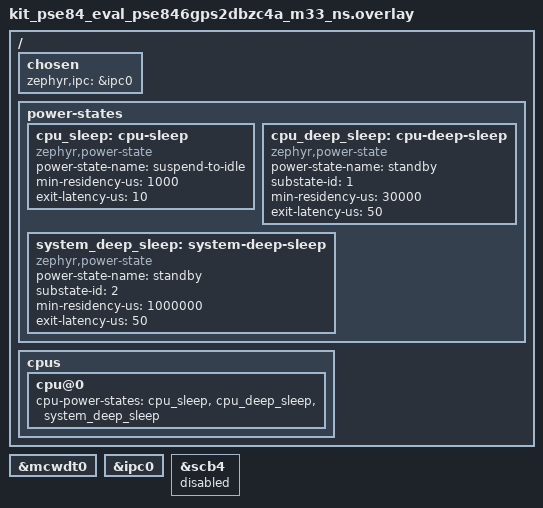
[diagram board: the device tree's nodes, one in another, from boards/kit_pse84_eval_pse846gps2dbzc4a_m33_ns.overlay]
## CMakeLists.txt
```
cmake_minimum_required(VERSION 3.20.0)

find_package(Zephyr REQUIRED HINTS $ENV{ZEPHYR_BASE})

# Inject the z_pm out-of-tree TF-M secure partition into the TF-M build.
# Set after find_package(Zephyr) so zephyr_property_target exists, but
# before project() so the TF-M ExternalProject CMake picks it up.
set(Z_PM_PARTITION_DIR ${CMAKE_CURRENT_LIST_DIR}/../tfm_partitions/z_pm)
set_property(TARGET zephyr_property_target
    APPEND PROPERTY TFM_CMAKE_OPTIONS
    -DTFM_EXTRA_MANIFEST_LIST_FILES=${Z_PM_PARTITION_DIR}/manifest_list.yaml
    -DTFM_EXTRA_PARTITION_PATHS=${Z_PM_PARTITION_DIR}
    # Round-7 debug: halt (spin) in tfm_core_panic instead of doing
    # NVIC_SystemReset. Lets a debugger read the exception frame that
    # BusFault_Handler / SecureFault_Handler stashed via EXCEPTION_INFO().
    # Remove for production builds.
    -DCONFIG_TFM_HALT_ON_CORE_PANIC=ON
)

project(cm33_ns_blinki)

# Drop the SoC's default pm_state_set + its PRE_KERNEL_1 SYS_INIT
# (which bus-faults from NS under TF-M when CONFIG_PM=y). We provide
# our own pm_state_set in src/power.c.
get_target_property(zephyr_sources zephyr SOURCES)
list(REMOVE_ITEM zephyr_sources
     ${ZEPHYR_BASE}/soc/infineon/edge/pse84/power.c)
set_property(TARGET zephyr PROPERTY SOURCES ${zephyr_sources})

target_sources(app PRIVATE
    src/main.c
    src/indicator.c
    src/power.c
    src/z_pm_client.c
)

# Pick up psa_manifest/sid.h generated by the TF-M build (provides
# Z_PM_SERVICE_HANDLE for the partition we injected above).
target_include_directories(app PRIVATE
    $<TARGET_PROPERTY:tfm,TFM_BINARY_DIR>/api_ns/interface/include
)
```

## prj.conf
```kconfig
CONFIG_BUILD_OUTPUT_HEX=y
CONFIG_GPIO=y
CONFIG_BOOT_BANNER=y
# Enable the TF-M mailbox/relay so the CM55 non-secure image can reach
# the TF-M Secure Processing Environment running on this CM33-NS core.
# Must be set on BOTH the CM33-NS and CM55 images of the paired build.
CONFIG_PSOC_EDGE_M55_SRF_SUPPORT=y

# Phase 2: enable the Zephyr PM core. No custom power-states declared
# yet, so the default policy will idle the CPU via WFI between blinks
# but no SoC PM hooks fire. SysTick stays as the system tick for now.
CONFIG_PM=y
CONFIG_PM_POLICY_DEFAULT=y
#CONFIG_PM_DEVICE=y
#CONFIG_PM_DEVICE_SYSTEM_MANAGED=y
CONFIG_TICKLESS_KERNEL=y
CONFIG_MAIN_STACK_SIZE=4096
# Round-7 finding: pm_state_set runs on the idle thread. With FPU sharing on
# (CONFIG_FPU=y + CONFIG_FPU_SHARING=y), tfm_ns_interface_dispatch's prologue
# allocates a 136-byte fpu_ctx_full on the caller's stack before invoking the
# SG veneer. The default idle stack (320 B) survives that only on the shortest
# call chain (z_pm's thin wrapper). Deeper NS→S paths (e.g. Cy_SysPm_* NS-SRF
# branch → mtb_srf_pool_allocate → ifx_mtb_srf_call → psa_call →
# tfm_ns_interface_dispatch) blow past PSPLIM at the `sub sp, #136`. Fault
# shows as HardFault with HFSR.FORCED (STKOF UsageFault escalated).
# 2048 leaves ample headroom for the deepest expected NS→S chain.
CONFIG_IDLE_STACK_SIZE=2048
CONFIG_INIT_STACKS=y
CONFIG_FAULT_DUMP=2

# Phase 3: route the kernel tick onto MCWDT0/LPTIMER (declared in the
# overlay). MCWDT0 keeps clocking through DeepSleep; SysTick does not.
CONFIG_CORTEX_M_SYSTICK=n
CONFIG_INFINEON_LP_TIMER_PDL=y

# Round-7 debug: verbose secure logging + exception frame dump on
# fatal errors in the SPE. TFM_EXCEPTION_INFO_DUMP defaults to y but
# only prints when the SPM log level is DEBUG. TFM_HALT_ON_CORE_PANIC
# (halt instead of NVIC_SystemReset on tfm_core_panic) is a TF-M
# CMake option, appended to TFM_CMAKE_OPTIONS in cm33_ns/CMakeLists.txt.
#CONFIG_INSTRUMENTATION_TRIGGER_FUNCTION="instrumentation_trigger"
#CONFIG_INSTRUMENTATION=y
#CONFIG_INSTRUMENTATION_MODE_CALLGRAPH=y
#CONFIG_INSTRUMENTATION_EXCLUDE_FILE_LIST="isr_wrapper,xip,bitmask,version,spi,i2c,adc,pwm,wdt,usb,mem,cy_crypto,cy_ble,cy_tcpwm,cy_adc,cy_dac,cy_smartio,cy_sdhc,cmsis,crypto,dma,cy_mpc,cy_ppc,cy_trigmux,qspi,assert,bitarray"
#CONFIG_INSTRUMENTATION_EXCLUDE_FUNCTION_LIST="pm_device_runtime_is_enabled,device_is_ready,pm_device_is_busy,pm_device_wakeup_is_enabled,pm_device_action_run,main,k_busy_wait,sys_clock_elapsed,any_cpu_announcing,this_cpu_announcin,runq_bes,next_up,update_cache,sys_clock_cycle_get_32,arch_k_cycle_get_32,k_cycle_get_3,arch_irq_lock,arch_irq_unlock,timeout"
#CONFIG_INSTRUMENTATION_MODE_CALLGRAPH_TRACE_BUFFER_SIZE=65000
#CONFIG_INSTRUMENTATION_MODE_CALLGRAPH_BUFFER_OVERWRITE=y
#CONFIG_INSTRUMENTATION_STOPPER_FUNCTION="instrumentation_stopper"
#CONFIG_INSTRUMENTATION_DYNAMIC_TRIGGER=n
#CONFIG_LOG=n
#CONFIG_SHELL=n
#CONFIG_UART_CONSOLE=n
#CONFIG_PRINTK=n
#CONFIG_CONSOLE=n
#CONFIG_SERIAL=n
```

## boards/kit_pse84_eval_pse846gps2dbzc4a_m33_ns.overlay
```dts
/*
 * Copyright (c) 2026 Infineon Technologies AG
 *
 * SPDX-License-Identifier: Apache-2.0
 *
 * CM33 Non-Secure overlay for the 02_pse84_tfm_m33_m55_pm template.
 * Phase 3 of the porting plan: declare Zephyr power-states and route
 * the kernel tick onto MCWDT0 (LPTIMER), which survives DeepSleep.
 *
 * Numbers are placeholders chosen to keep
 * (min_residency_us + exit_latency_us) strictly increasing in the
 * cpu-power-states chosen list, which Zephyr's default residency
 * policy needs to pick the deepest state for any given idle window.
 * Final residencies will be re-measured per state.
 *
 * The source project (tmp/16_pse84_3img_rram_pm/m33_ns) also
 * disabled &uart2 and &peri0_group1_16bit_0 because it ran without
 * TF-M and reused the SCB2 console programmed by its custom CM33-S.
 * Project 02 uses TF-M with the standard Zephyr UART console, so
 * those disables are deliberately omitted.
 */

/ {
	chosen {
		zephyr,ipc = &ipc0;
	};
	power-states {
		cpu_sleep: cpu-sleep {
			compatible = "zephyr,power-state";
			power-state-name = "suspend-to-idle";
			min-residency-us = <1000>;
			exit-latency-us = <10>;
		};

		cpu_deep_sleep: cpu-deep-sleep {
			compatible = "zephyr,power-state";
			power-state-name = "standby";
			substate-id = <1>;
			min-residency-us = <30000>;
			exit-latency-us = <50>;
		};

		system_deep_sleep: system-deep-sleep {
			compatible = "zephyr,power-state";
			power-state-name = "standby";
			substate-id = <2>;
			min-residency-us = <1000000>;
			exit-latency-us = <50>;
		};

		/*
		 * DS-RAM (SUSPEND_TO_RAM) and DS-OFF (SOFT_OFF) are
		 * TODO for future implementation and currently NOT
		 * hooked into cpu-power-states below. The Phase-8
		 * scoped attempt at DS-RAM proved a one-shot
		 * warm-boot round-trip under TF-M but could not be
		 * cycled continuously without breaking the lighter
		 * DS states -- see DS_RAM_RETROSPECTIVE.md for the
		 * full write-up of what was tried and what would be
		 * required to finish it.
		 *
		 * system_deep_sleep_ram: system-deep-sleep-ram {
		 *         compatible = "zephyr,power-state";
		 *         power-state-name = "suspend-to-ram";
		 *         min-residency-us = <2000000>;
		 *         exit-latency-us = <500>;
		 * };
		 *
		 * system_deep_sleep_off: system-deep-sleep-off {
		 *         compatible = "zephyr,power-state";
		 *         power-state-name = "soft-off";
		 *         min-residency-us = <4000000>;
		 *         exit-latency-us = <100000>;
		 * };
		 */
	};

	cpus {
		cpu@0 {
			cpu-power-states = <&cpu_sleep
					    &cpu_deep_sleep
					    &system_deep_sleep>;
		};
	};
};

/* Enable MCWDT0 so the Infineon LPTIMER driver binds here and
 * provides the kernel tick. MCWDT0 keeps running across DeepSleep,
 * which the SysTick cannot do.
 */
&mcwdt0 {
	status = "okay";
};
&ipc0 {
    status = "okay";
};
&scb4{
    status = "disabled";
};
```

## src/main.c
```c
/*
 * Copyright (c) 2026
 *
 * SPDX-License-Identifier: Apache-2.0
 *
 * CM33 non-secure indicator-loop blinky for the kit_pse84_eval.
 * Phase 1 of the porting plan: drive the green RGB indicator only,
 * no PM core involvement yet.
 */
#include <stdio.h>
#include <zephyr/kernel.h>

#include "indicator.h"
#include "z_pm_client.h"
#include "cy_device.h"

#define BLINK_ON_MS 200

/* Per-state knob — pattern lifted from
 * tmp/16_pse84_3img_rram_pm/m33_ns/src/main.c. Uncomment exactly
 * ONE line to pick which PM state Zephyr's default residency
 * policy lands on during the sleep window between blinks.
 *
 * Residency thresholds come from cm33_ns/boards/kit_*.overlay
 * (min-residency-us + exit-latency-us); rows are ordered ascending.
 *
 *    ms  | state             | residency >=  | LED     | dispatch
 *   -----+-------------------+---------------+---------+-----------
 *      5 | cpu_sleep         |      1 010 us | red     | PDL direct
 *    100 | cpu_deep_sleep    |     30 050 us | blue    | PDL direct
 *   1500 | system_deep_sleep |  1 000 050 us | magenta | z_pm+PDL
 *
 * Round-7 finding: the CPU-side Cy_SysPm_Cpu{,Deep}Sleep entries
 * dispatch directly to PDL syspm from NS. The NS-side cy_syspm_v4.c is
 * compiled with CY_PDL_SYSPM_ENABLE_SRF_INTEG, so those calls pack an
 * SRF request and psa_call into IFX_EXT_SP; the S side runs the real
 * WFI at PC2. Prerequisite: CONFIG_IDLE_STACK_SIZE >= 2 KiB (Zephyr
 * default 320 B is too small for the tfm_ns_interface_dispatch
 * fpu_ctx_full alloca on this path).
 *
 * The 1500 ms system_deep_sleep entry additionally calls
 * Z_PM_OP_SET_DEEP_SLEEP_MODE via z_pm to program the AN237976
 * Table-2 DEEPSLEEP row on the Sys-domain PPUs (MAIN, SRAM0, SRAM1,
 * SYSCPU) + folded-in Layer-B DS bias.
 *
 * Deeper states (system_deep_sleep_ram / system_deep_sleep_off) are
 * TODO for future implementation; see DS_RAM_RETROSPECTIVE.md for the
 * Phase-8 scoped attempt and what would be required to finish it.
 */
 #define SLEEP_BETWEEN_BLINKS_MS 5 /* cpu_sleep                 */
// #define SLEEP_BETWEEN_BLINKS_MS 100 /* cpu_deep_sleep — direct PDL */
//#define SLEEP_BETWEEN_BLINKS_MS 1500 /* system_deep_sleep       */


volatile int instrumentation_marker;
volatile uint32_t heartbeat;
//extern uint32_t scb_enabled_before;
volatile uint32_t *peri0_gr1_address = 0x00000000;
volatile uint32_t peri0_gr1_scb2;
volatile uint32_t scb_before = 0xAAAAAAAA;
volatile uint32_t scb_after  = 0x55555555;
volatile uint32_t *auxiliar =0x00000000 ;
/* Trigger function: marks the point where instrumentation should
 * START recording. Referenced by CONFIG_INSTRUMENTATION_TRIGGER_FUNCTION.
 */
 
//Compiler options
// - used: Avoid optimization due to lack of use
// - noinline: Function as an external entity, real function calls.
__attribute__((used, noinline))
void instrumentation_trigger(void)
{
    instrumentation_marker = 1;
}
 
 
 
/* Stopper function: marks the point where instrumentation should
 * stop recording. Referenced by CONFIG_INSTRUMENTATION_STOPPER_FUNCTION.
 */
 
__attribute__((used, noinline))
void instrumentation_stopper(void)
{
    instrumentation_marker = 2;
}

int main(void)
{
	//printf("CM33-NS indicator blinky on %s\n", CONFIG_BOARD);

	indicator_init();
	heartbeat = 0;
	bool flag = 0;
	/* Phase 6 step 1: ping the z_pm secure partition to validate the
	 * out-of-tree partition + PSA call infrastructure end-to-end.
	 * Logs the result once at boot; does not affect the blink loop.
	 */
	uint32_t cookie = 0;
	psa_status_t st = z_pm_ping(&cookie);

	if (st == PSA_SUCCESS && cookie == Z_PM_PING_COOKIE) {
		printf("z_pm ping ok: cookie=0x%08x\n", cookie);
	} else {
		//printf("z_pm ping FAIL: status=%d cookie=0x%08x\n", (int)st,
		//       cookie);
	}
	//indicator_active_off();

	//clk_st = z_pm_clk_root_select_disable(6u);
	//clk_st = z_pm_clk_root_select_disable(7u);
	//clk_st = z_pm_clk_root_select_disable(8u);
	//cookie = 0;
	//k_busy_wait(BLINK_ON_MS * 1000U);
	//cookie = cookie + 1;
	//instrumentation_trigger();
	//k_msleep(SLEEP_BETWEEN_BLINKS_MS);
	//cookie++;
	//instrumentation_stopper();
	//if (cookie==5){
	//	indicator_active_on();
	//}
	//k_busy_wait(100000);
	//instrumentation_trigger();
	//psa_status_t clk_st = z_pm_clk_root_select_disable(10u);
	//instrumentation_trigger();	
	//k_msleep(SLEEP_BETWEEN_BLINKS_MS);
	//instrumentation_stopper();
	//clk_st = z_pm_clk_root_select_enable(10u);
	//k_busy_wait(0000);
	//indicator_active_on();
	
	/*SLAVE CONTROL
		peri0_gr1_address = &PERI_GR_SL_CTL(0,1);
		peri0_gr1_scb2 = (PERI_GR_SL_CTL(0,1) >> 7u) & 1u;
		PERI_GR_SL_CTL(0, 1) &= ~(1u << 7);
	*/


	/*POWER DOMAINS
	*/
		//auxiliar = &CY_PDCM_PD_SENSE(0);
		//scb_before = PWRMODE_BASE;
		psa_status_t op_result = z_pm_read_register(PWRMODE_BASE,&heartbeat);
		//heartbeat = *(uint32_t *)CY_PPU_PD1_BASE;
		//printk("%u\n",auxiliar);
		//*(volatile uint32_t *)CY_PPU_PD0_BASE &= ~(0xFu);  



	while(1){
		k_busy_wait(BLINK_ON_MS * 1000U);
		printk("%u\n",heartbeat);
		//indicator_active_off();
		//if (flag == 0){
			//instrumentation_trigger();
			//clk_st = z_pm_clk_root_select_disable(10u);

			//scb_before = (SCB_CTRL(0x42990000) >> 28U) & 1U;;
			//SCB_CTRL(0x429A0000) &= ~(1U << 28U);
		//k_msleep(SLEEP_BETWEEN_BLINKS_MS);
		//indicator_active_on();

	}
		//k_busy_wait(50000);
		
		//indicator_active_off();
		//if (flag == 0){
			//instrumentation_trigger();
			//clk_st = z_pm_clk_root_select_disable(10u);

			//scb_before = (SCB_CTRL(0x42990000) >> 28U) & 1U;;
			//SCB_CTRL(0x429A0000) &= ~(1U << 28U);
			//instrumentation_stopper();
			//clk_st = z_pm_clk_root_select_enable(10u);
			//scb_after = (SCB_CTRL(0x429A0000) >> 28U) & 1U;
			//SCB_CTRL(0x429A0000) |= (1U << 28U);
			//indicator_active_on();
			/*while(1){
				k_busy_wait(50000);
				//printk("%p\n", (void*)peri0_gr1_address);
			/	printk("%u\n",peri0_gr1_scb2);
				//printk("Before: %u, After: %u\n", (unsigned)scb_before, (unsigned)scb_after);

				//printk("a");
			}*/
		//}else{
		//	k_busy_wait(100000);
			//k_msleep(SLEEP_BETWEEN_BLINKS_MS);
		//	indicator_active_on();
		//}
		

		//k_busy_wait(100000);
		//printk("%u\n", (unsigned)cookie);*/


	return 0;
}
```

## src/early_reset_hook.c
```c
/*
 * Copyright (c) 2026
 * SPDX-License-Identifier: Apache-2.0
 *
 * Phase 8 (scoped DS-RAM): early reset hook that runs BEFORE C runtime
 * initialisation (in reset.S context, before z_prep_c). Its only job is
 * to undo the FPU/MVE power-gate that @c enter_ds_ram in power.c applied
 * just before WFI on the previous cycle.
 *
 * enter_ds_ram() power-gates CP10/CP11 via:
 *   SCS_CPPWR   |=  SCS_ENABLE_CPPWR_SU10_SU11;
 *   SCB->CPACR  &= ~SCB_ENABLE_CPACR_CP10_CP11;
 * because silicon requires it for the chip to fold to DEEPSLEEP_RAM
 * instead of plain DEEPSLEEP. On the DS-RAM wake reset, the NS view of
 * both registers is preserved (they are not part of the reset scope),
 * so the very first FPU / MVE instruction executed after reset — which
 * is picolibc's memset/memcpy over .bss/.data during C runtime init —
 * traps NOCP and escalates to HardFault before @c main() ever runs.
 *
 * Re-enabling CP10/CP11 here in the reset.S window (before z_prep_c and
 * before any .bss touch) fixes that. Runs on POR too — a no-op in that
 * case because CPACR/CPPWR come up in their enabled state at cold boot.
 *
 * Requires @c CONFIG_SOC_EARLY_RESET_HOOK=y. See
 * ~/zephyrproject/zephyr/kernel/Kconfig.init and
 * ~/zephyrproject/zephyr/arch/arm/core/cortex_m/reset.S for the wiring.
 *
 * Reference: tmp/17_pse84_ds_ram_exact/m33_ns/src/early_reset_hook.c.
 */

#include <cmsis_core.h>

#include "cy_device.h"

void soc_early_reset_hook(void)
{
	SCS_CPPWR &= ~SCS_ENABLE_CPPWR_SU10_SU11;
	SCB->CPACR |= SCB_ENABLE_CPACR_CP10_CP11;
	__DSB();
	__ISB();
}
```

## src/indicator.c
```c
/*
 * Copyright (c) 2026 Infineon Technologies AG
 * SPDX-License-Identifier: Apache-2.0
 */

/**
 * @file
 * @brief RGB LED indicator implementation (PORT16 P16.5/6/7).
 *
 * led0 = red (P16.7), led1 = green (P16.6), led2 = blue (P16.5)
 * — aliases come from the kit_pse84_eval common DTSI.
 *
 * Plan §6 colour map:
 *   green        = active phase
 *   red          = PM_STATE_SUSPEND_TO_IDLE   (cpu_sleep)
 *   blue         = PM_STATE_STANDBY sub 1     (cpu_deep_sleep)
 *   magenta R+B  = PM_STATE_STANDBY sub 2     (system_deep_sleep)
 *   cyan G+B     = PM_STATE_SUSPEND_TO_RAM    (system_deep_sleep_ram)
 *   white R+G+B  = PM_STATE_SOFT_OFF          (system_deep_sleep_off, latched)
 */

#include <zephyr/devicetree.h>
#include <zephyr/drivers/gpio.h>

#include "indicator.h"

static const struct gpio_dt_spec led_red =
    GPIO_DT_SPEC_GET(DT_ALIAS(led0), gpios);
static const struct gpio_dt_spec led_green =
    GPIO_DT_SPEC_GET(DT_ALIAS(led1), gpios);
static const struct gpio_dt_spec led_blue =
    GPIO_DT_SPEC_GET(DT_ALIAS(led2), gpios);

static void led_set(const struct gpio_dt_spec *led, int value)
{
	(void)gpio_pin_set_dt(led, value);
}

void indicator_init(void)
{
	(void)gpio_pin_configure_dt(&led_red, GPIO_OUTPUT_INACTIVE);
	(void)gpio_pin_configure_dt(&led_green, GPIO_OUTPUT_INACTIVE);
	(void)gpio_pin_configure_dt(&led_blue, GPIO_OUTPUT_INACTIVE);
}

void indicator_active_on(void) { led_set(&led_red, 1); }
void indicator_active_off(void) { led_set(&led_red, 0); }

void indicator_cpu_sleep_on(void) { led_set(&led_red, 1); }
void indicator_cpu_sleep_off(void) { led_set(&led_red, 0); }

void indicator_cpu_deep_sleep_on(void) { led_set(&led_blue, 1); }
void indicator_cpu_deep_sleep_off(void) { led_set(&led_blue, 0); }

void indicator_system_deep_sleep_on(void)
{
	led_set(&led_red, 1);
	led_set(&led_blue, 1);
}
void indicator_system_deep_sleep_off(void)
{
	led_set(&led_red, 0);
	led_set(&led_blue, 0);
}

void indicator_system_ds_ram_on(void)
{
	led_set(&led_green, 1);
	led_set(&led_blue, 1);
}
void indicator_system_ds_ram_off(void)
{
	led_set(&led_green, 0);
	led_set(&led_blue, 0);
}

void indicator_system_ds_off_latch(void)
{
	led_set(&led_red, 1);
	led_set(&led_green, 1);
	led_set(&led_blue, 1);
}
```

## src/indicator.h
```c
/*
 * Copyright (c) 2026 Infineon Technologies AG
 * SPDX-License-Identifier: Apache-2.0
 */

/**
 * @file
 * @brief RGB LED indicator API for per-state visualisation.
 *
 * Plan §6: green = active phase; red/blue/magenta/cyan/white =
 * sleep-state indicators. One function per role so the dispatcher
 * in power.c reads as a straight call list.
 *
 * Implemented in indicator.c.
 */

#ifndef APP_INDICATOR_H_
#define APP_INDICATOR_H_

#ifdef __cplusplus
extern "C" {
#endif

/** @brief Configure all three RGB LEDs as outputs, all OFF. */
void indicator_init(void);

/** @brief Active-phase indicator (green) ON. */
void indicator_active_on(void);
/** @brief Active-phase indicator (green) OFF. */
void indicator_active_off(void);

/** @brief PM_STATE_SUSPEND_TO_IDLE (cpu_sleep) — red ON. */
void indicator_cpu_sleep_on(void);
void indicator_cpu_sleep_off(void);

/** @brief PM_STATE_STANDBY substate 1 (cpu_deep_sleep) — blue ON. */
void indicator_cpu_deep_sleep_on(void);
void indicator_cpu_deep_sleep_off(void);

/** @brief PM_STATE_STANDBY substate 2 (system_deep_sleep) — magenta ON. */
void indicator_system_deep_sleep_on(void);
void indicator_system_deep_sleep_off(void);

/** @brief PM_STATE_SUSPEND_TO_RAM (system_deep_sleep_ram) — cyan ON. */
void indicator_system_ds_ram_on(void);
void indicator_system_ds_ram_off(void);

/** @brief PM_STATE_SOFT_OFF (system_deep_sleep_off) — white ON, latched. */
void indicator_system_ds_off_latch(void);

#ifdef __cplusplus
}
#endif

#endif /* APP_INDICATOR_H_ */
```

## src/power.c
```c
/*
 * Copyright (c) 2026 Infineon Technologies AG
 * SPDX-License-Identifier: Apache-2.0
 *
 * Zephyr PM dispatcher for the CM33-NS image.
 *
 * Round 7: all three currently-implemented PM entry points call
 * PDL syspm directly from NS. The NS-side cy_syspm_v4.c is compiled
 * with CY_PDL_SYSPM_ENABLE_SRF_INTEG (auto-defined by cy_syspm_srf.h
 * because at least one of the four CYCFG_PPC_SECURED_{SRSS_MAIN,
 * SRSS_HIB_DATA, PWRMODE_PWRMODE, M55APPCPUSS} bits is 1U). That
 * activates the SRF branch inside each Cy_SysPm_Cpu*Enter*Sleep
 * function, which packs an SRF request and psa_call()s into
 * IFX_EXT_SP; the S-side handler runs the actual SLEEPDEEP+WFI at
 * PC2.  No project-local partition wrap is needed for these APIs.
 *
 * z_pm still exists (see tfm_partitions/z_pm/) but only exposes
 * Z_PM_OP_PING today. It is the placeholder for future ops that
 * PDL DOES NOT SRF-wrap: Cy_SysPm_SetSysDeepSleepMode,
 * Cy_SysPm_SetSOCMEMDeepSleepMode, CM55-side hibernate, Layer-B
 * bias, retention patterns.
 *
 * The SoC default pm_state_set (in soc/infineon/edge/pse84/power.c)
 * is dropped from the build by the application CMakeLists — its
 * PRE_KERNEL_1 SYS_INIT calls Cy_SysPm_SetDeepSleepMode which is
 * NOT SRF-wrapped and bus-faults from NS.
 *
 * Prerequisite for the direct-NS path: CONFIG_IDLE_STACK_SIZE must
 * be large enough for tfm_ns_interface_dispatch's fpu_ctx_full
 * alloca (136 bytes) on top of the pool_allocate + Cy_SysPm_*
 * frames. See prj.conf; 2 KiB works, the Zephyr default 320 bytes
 * does not.
 */

#include <zephyr/kernel.h>
#include <zephyr/init.h>
#include <zephyr/pm/pm.h>

#include <cmsis_core.h>

#include "cy_mcwdt.h"
#include "cy_syspm.h"

#include "indicator.h"
#include "z_pm_client.h"

/**
 * @brief Switch IRQ masking from BASEPRI to PRIMASK before WFI.
 *
 * @details
 * Zephyr enters ::pm_state_set with BASEPRI raised by
 * @c irq_lock(), which masks every maskable interrupt including the
 * timer that is supposed to wake us. PSE84 / Cortex-M33 only honours
 * wake from standby/sleep when the wake source is signalled with
 * PRIMASK set; BASEPRI keeps the interrupt pending forever.
 *
 * This helper matches the SoC default @c pm_state_set:
 * @c __disable_irq() sets PRIMASK, @c irq_unlock(0) clears BASEPRI.
 * @ref pm_state_exit_post_ops re-enables interrupts via
 * @c __enable_irq() after WFI returns.
 */
static inline void pm_irq_prologue(void)
{
	__disable_irq();
	irq_unlock(0);
}

/**
 * @brief Enter PM_STATE_SUSPEND_TO_IDLE (SLEEPDEEP=0 + WFI).
 *
 * @details
 * Toggles the red indicator LED, masks IRQs, then calls
 * @c Cy_SysPm_CpuEnterSleep. The NS-side PDL takes the SRF branch
 * (see file header) which packs a PSA request to @c IFX_EXT_SP;
 * the S-side handler executes the real WFI at PC2. Returns after
 * the wake interrupt is delivered to NS.
 *
 * Called by ::pm_state_set. Blocking; runs on the idle thread with
 * PRIMASK set.
 */
static void enter_cpu_sleep(void)
{
	//indicator_cpu_sleep_on();
	pm_irq_prologue();
	(void)Cy_SysPm_CpuEnterSleep(CY_SYSPM_WAIT_FOR_INTERRUPT);
	//indicator_cpu_sleep_off();
}

/**
 * @brief Enter PM_STATE_STANDBY substate 1 (cpu_deep_sleep).
 *
 * @details
 * SLEEPDEEP=1 + WFI, plus PDL syspm callbacks and PPU-trim fixups
 * executed on the S side. Same NS→SRF→S path as
 * @ref enter_cpu_sleep, dispatched via
 * @c Cy_SysPm_CpuEnterDeepSleep. Toggles the blue indicator LED
 * around the call. Returns after the wake IRQ.
 *
 * SRSS collapses the system to deep-sleep automatically once every
 * CPU has voted; a single CM33-NS caller is sufficient because CM55
 * is either parked or has already voted its own deep-sleep.
 */
static void enter_cpu_deep_sleep(void)
{
	//indicator_cpu_deep_sleep_on();
	pm_irq_prologue();
	(void)Cy_SysPm_CpuEnterDeepSleep(CY_SYSPM_WAIT_FOR_INTERRUPT);
	//indicator_cpu_deep_sleep_off();
}

/**
 * @brief Enter PM_STATE_STANDBY substate 2 (system_deep_sleep).
 *
 * @details
 * Same CPU-level primitive as @ref enter_cpu_deep_sleep
 * (@c Cy_SysPm_CpuEnterDeepSleep), but with a per-transition system
 * setup performed first via the z_pm secure partition:
 *
 *   1. @c z_pm_set_deep_sleep_mode(CY_SYSPM_MODE_DEEPSLEEP) — S side
 *      runs @c Cy_SysPm_SetDeepSleepMode(DEEPSLEEP) which programs
 *      the AN237976 Table-2 DEEPSLEEP column (MAIN, SRAM0, SRAM1,
 *      SYSCPU, PD1, APPCPUSS, APPCPU, SOCMEM, U55) so the SoC
 *      actually collapses to system deep sleep when every CPU has
 *      voted. The same op also applies the Layer-B BGREF LP +
 *      CoreBuck DS knobs that Phase 6 measurement deferred out of
 *      the at-boot bias — safe here because reaching this state
 *      commits us to a system-DS transition.
 *   2. @ref pm_irq_prologue — swap BASEPRI for PRIMASK so the wake
 *      IRQ can pend.
 *   3. @c Cy_SysPm_CpuEnterDeepSleep — SRF-wrapped by the PDL; the S
 *      side runs SLEEPDEEP+WFI at PC2.
 *
 * The PPU / Layer-B state programmed here is SRSS-global and thus
 * "sticky" across future entries. That is fine as long as this is the
 * only path that reprograms it: Phases 8 / 9 will re-issue
 * @c z_pm_set_deep_sleep_mode with @c CY_SYSPM_MODE_DEEPSLEEP_RAM /
 * @c CY_SYSPM_MODE_DEEPSLEEP_OFF from their own dispatchers.
 *
 * Uses the magenta indicator LED.
 */
static void enter_system_deep_sleep(void)
{
	//indicator_system_deep_sleep_on();

	psa_status_t st =
	    z_pm_set_deep_sleep_mode((uint32_t)CY_SYSPM_MODE_DEEPSLEEP);
	if (st != PSA_SUCCESS) {

	}

	pm_irq_prologue();
	(void)Cy_SysPm_CpuEnterDeepSleep(CY_SYSPM_WAIT_FOR_INTERRUPT);
	//indicator_system_deep_sleep_off();
}

/**
 * @brief Zephyr PM hook: enter the requested low-power state.
 *
 * @details
 * Called by the Zephyr PM subsystem from the idle thread when its
 * residency policy elects a low-power state for the current idle
 * window. Runs with @c irq_lock() held (BASEPRI raised). Each
 * per-state helper calls @ref pm_irq_prologue to switch to PRIMASK
 * before WFI so the wake IRQ can actually reach the CPU.
 *
 * State mapping (residency thresholds live in the board overlay
 * @c cm33_ns/boards/kit_*.overlay; LED colours are per @ref indicator.h):
 *
 * | State + substate         | Handler                      | LED     |
 * |--------------------------|------------------------------|---------|
 * | SUSPEND_TO_IDLE          | @ref enter_cpu_sleep         | red     |
 * | STANDBY substate 1       | @ref enter_cpu_deep_sleep    | blue    |
 * | STANDBY substate 2       | @ref enter_system_deep_sleep | magenta |
 *
 * SUSPEND_TO_RAM / SOFT_OFF are TODO for future implementation and are
 * NOT declared in the board overlay, so Zephyr will never dispatch them
 * here. See DS_RAM_RETROSPECTIVE.md for the Phase-8 scoped attempt at
 * DS-RAM and what would be required to finish it.
 *
 * @param state       The Zephyr PM state the residency policy picked.
 * @param substate_id Vendor-defined substate index (only meaningful
 *                    for @c PM_STATE_STANDBY here).
 *
 * @note Overrides Zephyr's weak default. The SoC-supplied
 *       @c pm_state_set in soc/infineon/edge/pse84/power.c is dropped
 *       from the build by cm33_ns/CMakeLists.txt because its
 *       PRE_KERNEL_1 SYS_INIT bus-faults from NS under TF-M.
 */
void pm_state_set(enum pm_state state, uint8_t substate_id)
{
	switch (state) {
	case PM_STATE_SUSPEND_TO_IDLE:
		enter_cpu_sleep();
		break;
	case PM_STATE_STANDBY:
		switch (substate_id) {
		case 1U:
			enter_cpu_deep_sleep();
			break;
		case 2U:
			enter_system_deep_sleep();
			break;
		default:
			break;
		}
		break;
	default:
		break;
	}
}

/**
 * @brief Zephyr PM hook: post-WFI cleanup.
 *
 * @details
 * Called by the Zephyr PM subsystem after ::pm_state_set returns
 * from WFI. Symmetric to @ref pm_irq_prologue: clears PRIMASK
 * (which the prologue set) so normal interrupt delivery resumes.
 * BASEPRI is left at 0 (the prologue's @c irq_unlock(0) cleared
 * it); Zephyr's own scheduler-lock/unlock takes over from here.
 *
 * @param state       Same value passed to the paired ::pm_state_set.
 * @param substate_id Same value passed to the paired ::pm_state_set.
 */
void pm_state_exit_post_ops(enum pm_state state, uint8_t substate_id)
{
	ARG_UNUSED(state);
	ARG_UNUSED(substate_id);
	__enable_irq();
}

/**
 * @brief Pre-emptively disable MCWDT0 before the Zephyr LPTIMER driver
 *        touches it.
 *
 * @details
 * Reference: tmp/16_pse84_3img_rram_pm/m33_ns/src/power.c :: ifx_pm_init.
 * Cy_MCWDT_Init returns @c CY_MCWDT_BAD_PARAM if any of the three
 * counters is already enabled, and the SE-ROM / RRAM boot leaves the
 * MCWDT0 counters running on cold boot. Without this preemptive
 * disable, drivers/timer/infineon_lp_timer_pdl.c can fail silently:
 * lptimer_init returns -EINVAL, the system clock never starts, and
 * k_msleep hangs forever waiting for a tick.
 *
 * Runs at @c PRE_KERNEL_1 with priority 0 to beat the LPTIMER driver
 * (@c PRE_KERNEL_2 / @c CONFIG_SYSTEM_CLOCK_INIT_PRIORITY). MCWDT_STRUCT0
 * is NS-accessible under the current PPC config (the LPTIMER driver
 * running from NS at PRE_KERNEL_2 proves that).
 */
static int ns_preempt_mcwdt0_disable(void)
{
	Cy_MCWDT_Unlock(MCWDT_STRUCT0);
	Cy_MCWDT_Disable(MCWDT_STRUCT0,
			 CY_MCWDT_CTR0 | CY_MCWDT_CTR1 | CY_MCWDT_CTR2, 100U);
	Cy_MCWDT_ClearInterrupt(MCWDT_STRUCT0,
				CY_MCWDT_CTR0 | CY_MCWDT_CTR1 | CY_MCWDT_CTR2);
	Cy_MCWDT_SetInterruptMask(MCWDT_STRUCT0, 0U);
	return 0;
}

SYS_INIT(ns_preempt_mcwdt0_disable, PRE_KERNEL_1, 0);

/**
 * @brief Kick the z_pm partition's Layer-B static-bias setup.
 *
 * @details
 * Delegates to @ref z_pm_layer_b_init which psa_calls the z_pm secure
 * partition. That op runs at PC2 and programs the SRSS_MAIN /
 * PWRMODE / core-buck registers that NS cannot touch:
 * @c Cy_SysPm_Init, @c Cy_SysClk_ClkBakSetSource(PILO),
 * BGREF LP, CoreBuck 0.70 V / LP / override on, IHO/IMO DS-off.
 * See tfm_partitions/z_pm/z_pm_partition.c :: z_pm_op_layer_b_init
 * for the exact sequence and the porting plan Phase 6 for rationale.
 *
 * Runs at @c APPLICATION priority 0 (after the TF-M NS interface
 * comes up at @c POST_KERNEL and after every driver has initialised)
 * so psa_call has everything it needs. The Layer-B changes only
 * affect deep-sleep-time behaviour, so running late does not disturb
 * active-mode operation.
 *
 * Logs the result once; failure is non-fatal (system still runs, just
 * with the SE-ROM defaults which leak more in DS).
 */
static int ns_layer_b_init(void)
{
	psa_status_t st = z_pm_layer_b_init();

	if (st == PSA_SUCCESS) {
	} else {
	}
	return 0;
}

SYS_INIT(ns_layer_b_init, APPLICATION, 0);
```

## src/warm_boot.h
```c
/*
 * Copyright (c) 2026
 * SPDX-License-Identifier: Apache-2.0
 *
 * DS-RAM warm-boot diagnostic token (Phase 8).
 *
 * `Z_PM_OP_ENTER_DS_RAM` on the S side writes @ref WARM_BOOT_TOKEN_DS_RAM
 * into @c RTC->BREG_SET1[@ref WARM_BOOT_BREG_INDEX] immediately before
 * the caller's WFI. After the next reset (whether DS-RAM wake, XRES, or
 * watchdog) the NS `main()` banner reads (and clears) the token to
 * confirm that the previous boot actually reached WFI and that the chip
 * came back through the DS-RAM path rather than dying mid-entry.
 *
 * The token is purely diagnostic and does NOT participate in any
 * warm-boot-entry-pointer mechanism — PSE84's L1-boot does not use one;
 * cold and warm boot follow the same path. Use `Cy_SysPm_GetBootMode()`
 * for the actual boot-cause check.
 *
 * RTC BREGs are battery-backed and survive every reset short of POR.
 * Slot index 1 was picked to match tmp/17_pse84_ds_ram_exact's choice
 * (slot 0 is the PDL's nominal `CY_SYSPM_BOOTROM_ENTRYPOINT_ADDR`).
 *
 * Keep the constants in this header in lock-step with the copies in
 * tfm_partitions/z_pm/z_pm_partition.c :: Z_PM_OP_ENTER_DS_RAM.
 */

#ifndef APP_WARM_BOOT_H_
#define APP_WARM_BOOT_H_

#define WARM_BOOT_BREG_INDEX 1U
#define WARM_BOOT_TOKEN_DS_RAM 0x16D5DA01U /* "16-DS-DA01" tag */

#endif /* APP_WARM_BOOT_H_ */
```

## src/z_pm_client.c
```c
/*
 * Copyright (c) 2026
 * SPDX-License-Identifier: Apache-2.0
 *
 * NS-side stubs for the z_pm out-of-tree TF-M partition. Marshals args
 * into PSA invecs/outvecs and calls the partition's stateless service
 * handle (Z_PM_SERVICE_HANDLE from psa_manifest/sid.h).
 */

#include <stdint.h>

#include "psa/client.h"
#include "psa_manifest/sid.h"

#include "z_pm_client.h"

#ifndef IOVEC_LEN
#define IOVEC_LEN(x) (sizeof(x) / sizeof((x)[0]))
#endif

psa_status_t z_pm_ping(uint32_t *out_cookie)
{
	if (out_cookie == NULL) {
		return PSA_ERROR_INVALID_ARGUMENT;
	}

	psa_outvec out_vec[] = {
	    {.base = out_cookie, .len = sizeof(*out_cookie)},
	};

	return psa_call(Z_PM_SERVICE_HANDLE, Z_PM_OP_PING, NULL, 0, out_vec,
			IOVEC_LEN(out_vec));
}

psa_status_t z_pm_layer_b_init(void)
{
	return psa_call(Z_PM_SERVICE_HANDLE, Z_PM_OP_LAYER_B_INIT, NULL, 0,
			NULL, 0);
}

psa_status_t z_pm_set_deep_sleep_mode(uint32_t mode)
{
	psa_invec in_vec[] = {
	    {.base = &mode, .len = sizeof(mode)},
	};

	return psa_call(Z_PM_SERVICE_HANDLE, Z_PM_OP_SET_DEEP_SLEEP_MODE,
			in_vec, IOVEC_LEN(in_vec), NULL, 0);
}

psa_status_t z_pm_clk_root_select_enable(uint32_t index)
{
    psa_invec in_vec[] = {
        {.base = &index, .len = sizeof(index)},
    };
    return psa_call(Z_PM_SERVICE_HANDLE, Z_PM_OP_CLK_ROOT_SELECT_ENABLE,
                    in_vec, IOVEC_LEN(in_vec), NULL, 0);
}

psa_status_t z_pm_clk_root_select_disable(uint32_t index)
{
    	psa_invec in_vec[] = {
        	{.base = &index, .len = sizeof(index)},
    	};
    return psa_call(Z_PM_SERVICE_HANDLE, Z_PM_OP_CLK_ROOT_SELECT_DISABLE,
                    in_vec, IOVEC_LEN(in_vec), NULL, 0);
}

psa_status_t z_pm_read_register(uint32_t address, uint32_t *value)
{
    	psa_invec in_vec[] = {
        	{ .base = &address, .len = sizeof(address) },
    	};

    	psa_outvec out_vec[] = {
        	{ .base = value, .len = sizeof(*value) },
    	};

    	return psa_call(Z_PM_SERVICE_HANDLE, Z_PM_OP_READ_REGISTER,
                   	in_vec, IOVEC_LEN(in_vec),
                    	out_vec, IOVEC_LEN(out_vec));
}

/*psa_status_t z_pm_write_register(uint32_t address, uint32_t value)
{
    	 psa_invec in_vec[] = {
        	{ .base = &address, .len = sizeof(address) },
        	{ .base = &value,   .len = sizeof(value)   },
   	 };

    return psa_call(Z_PM_SERVICE_HANDLE, Z_PM_OP_WRITE_REGISTER,
                    in_vec, IOVEC_LEN(in_vec),
                    out_vec, IOVEC_LEN(out_vec));
}*/
```

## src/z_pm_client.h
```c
/*
 * Copyright (c) 2026
 * SPDX-License-Identifier: Apache-2.0
 *
 * Non-secure client API for the z_pm out-of-tree TF-M partition.
 *
 * The partition lives in apps/02_pse84_tfm_m33_m55_pm/tfm_partitions/z_pm/
 * and is injected into the TF-M build via TFM_EXTRA_MANIFEST_LIST_FILES /
 * TFM_EXTRA_PARTITION_PATHS from cm33_ns/CMakeLists.txt.
 *
 * Scope: only the ops that are NOT already reachable via the PDL's
 * built-in SRF integration. Today that is:
 *   - Z_PM_OP_PING         — round-trip proof-of-life.
 *   - Z_PM_OP_LAYER_B_INIT — once-at-boot static bias (SRSS_MAIN /
 *     PWRMODE writes: Cy_SysPm_Init, ClkBakSetSource(PILO), BGREF LP,
 *     CoreBuck DS knobs, IHO/IMO DS-off).
 *
 * The three SRF-covered sleep entry points (Cy_SysPm_CpuEnter{,Deep}Sleep,
 * CM33-side Cy_SysPm_SystemEnterHibernate) are called directly by
 * cm33_ns/src/power.c — see z_pm_partition.c header for the rationale.
 *
 * Op IDs are passed as the `type` argument of psa_call. Keep this enum in
 * sync with tfm_partitions/z_pm/z_pm_partition.c.
 */

#ifndef Z_PM_CLIENT_H_
#define Z_PM_CLIENT_H_

#include <stdint.h>

#include "psa/error.h"

#ifdef __cplusplus
extern "C" {
#endif

/* Op IDs - must match z_pm_partition.c */
#define Z_PM_OP_PING 1
#define Z_PM_OP_LAYER_B_INIT 2
#define Z_PM_OP_SET_DEEP_SLEEP_MODE 3
#define Z_PM_OP_CLK_ROOT_SELECT_ENABLE  4
#define Z_PM_OP_CLK_ROOT_SELECT_DISABLE 5
#define Z_PM_OP_READ_REGISTER 6
//#define Z_PM_OP_WRITE_REGISTER 7

#define Z_PM_PING_COOKIE 0xABCD1234u

/**
 * @brief Round-trip ping the z_pm secure partition.
 *
 * On success, writes Z_PM_PING_COOKIE to *out_cookie.
 *
 * @retval PSA_SUCCESS On success; @p out_cookie contains the cookie.
 * @retval PSA_ERROR_* From psa_call.
 */
psa_status_t z_pm_ping(uint32_t *out_cookie);

/**
 * @brief Run the Layer-B static-bias setup on the S side.
 *
 * Executes once at NS boot (from a SYS_INIT in power.c). Reaches the
 * PSA-ROT-only SRSS / PWRMODE / core-buck registers that NS cannot
 * touch directly.
 *
 * Phase 6 empirical bisection on this SoC showed that the "aggressive"
 * Layer-B knobs (Cy_SysPm_Init recall, ClkBakSetSource(PILO), BGREF LP,
 * CoreBuck DS voltage / mode / override) only pay off once the SoC
 * actually enters a full system deep sleep. That requires Phase 7's
 * per-transition Table-2 PPU programming. On the current CPU-only-DS
 * path those knobs either add small constant leak or override
 * TF-M-S's cycfg defaults. They are deferred to Phase 7 and folded
 * into Z_PM_OP_SET_DEEP_SLEEP_MODE at that time.
 *
 * The minimal handler kept in Phase 6 only clears the IHO / IMO
 * deep-sleep keep-alive bits (harmless on this build — they are 0
 * by default, so this is defensive for future SoC / cycfg drift).
 * PILO is intentionally left running so MCWDT0 (kernel tick) keeps
 * counting.
 *
 * @retval PSA_SUCCESS       On success.
 * @retval PSA_ERROR_*       From psa_call.
 */
psa_status_t z_pm_layer_b_init(void);

/**
 * @brief Program the SoC-global deep-sleep mode + Phase-7 Layer-B knobs.
 *
 * Wraps @c Cy_SysPm_SetDeepSleepMode(mode) on the S side. That call
 * programs the AN237976 Table-2 row of PPU retention settings that will
 * apply once every CPU has voted deep sleep (MAIN / SRAM0 / SRAM1 /
 * SYSCPU / PD1 / APPCPUSS / APPCPU / SOCMEM / U55). All those PPU
 * registers live in the PSA-ROT PC2 PPC group and are unreachable from
 * NS — which is why this has to go through z_pm.
 *
 * The S handler also applies the BGREF LP + CoreBuck DS knobs that
 * Phase 6 measured as adding leak on the CPU-only-DS path. They are
 * safe here because reaching this op means the caller is committing
 * to a system-DS transition.
 *
 * Called by cm33_ns/src/power.c :: enter_system_deep_sleep just before
 * @c Cy_SysPm_CpuEnterDeepSleep. Not called on the plain
 * @c cpu_deep_sleep path (that state is CPU-local).
 *
 * @param mode  One of @c CY_SYSPM_MODE_DEEPSLEEP,
 *              @c CY_SYSPM_MODE_DEEPSLEEP_RAM,
 *              @c CY_SYSPM_MODE_DEEPSLEEP_OFF (cast to uint32_t — the
 *              wrapper avoids pulling cy_syspm.h into this header to
 *              keep the PDL out of NS translation units that don't need
 *              it).
 *
 * @retval PSA_SUCCESS               Mode programmed successfully.
 * @retval PSA_ERROR_INVALID_ARGUMENT @p mode out of range.
 * @retval PSA_ERROR_GENERIC_ERROR    Cy_SysPm_SetDeepSleepMode failed on
 *                                    the S side.
 * @retval PSA_ERROR_*                From psa_call.
 */
psa_status_t z_pm_set_deep_sleep_mode(uint32_t mode);

psa_status_t z_pm_clk_root_select_enable(uint32_t index);
psa_status_t z_pm_clk_root_select_disable(uint32_t index);
psa_status_t z_pm_read_register(uint32_t address, uint32_t *value);
//psa_status_t z_pm_write_register(uint32_t address, uint32_t value);

#ifdef __cplusplus
}
#endif

#endif /* Z_PM_CLIENT_H_ */
```
